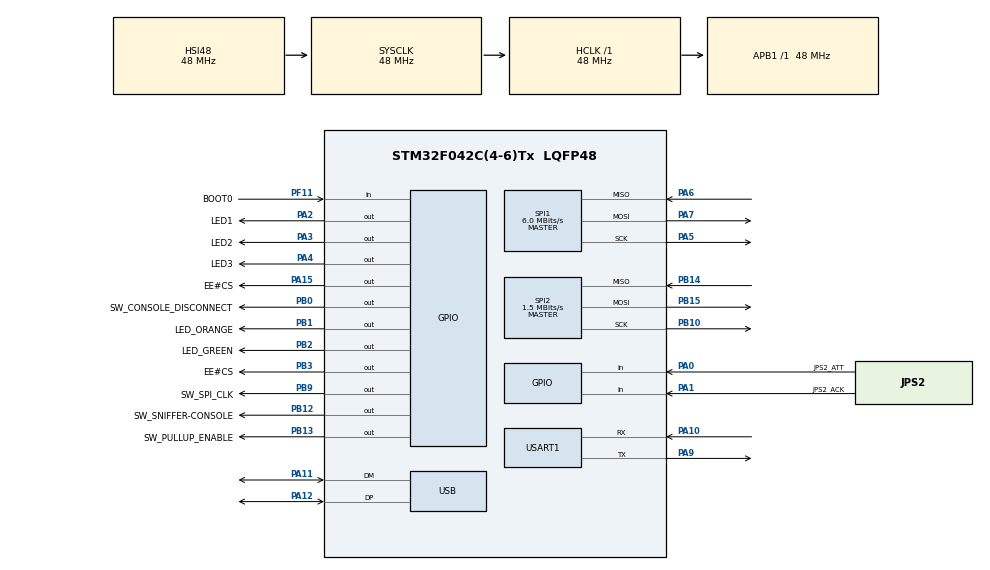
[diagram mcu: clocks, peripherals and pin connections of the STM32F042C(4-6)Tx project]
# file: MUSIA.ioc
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IWDG.Prescaler=IWDG_PRESCALER_32
Mcu.Family=STM32F0
Mcu.Name=STM32F042C(4-6)Tx
Mcu.Package=LQFP48
NVIC.USB_IRQn=true\:0\:0\:false\:false\:true\:false
PA0.GPIO_Label=JPS2_ATT
PA0.Signal=GPIO_Input
PA1.GPIO_Label=JPS2_ACK
PA1.Signal=GPIO_Input
PA10.Mode=Asynchronous
PA10.Signal=USART1_RX
PA11.Mode=Device
PA11.Signal=USB_DM
PA12.Mode=Device
PA12.Signal=USB_DP
PA13.Mode=Serial_Wire
PA13.Signal=SYS_SWDIO
PA14.Mode=Serial_Wire
PA14.Signal=SYS_SWCLK
PA15.GPIO_Label=EE\#CS
PA15.Signal=GPIO_Output
PA2.GPIO_Label=LED1
PA2.Signal=GPIO_Output
PA3.GPIO_Label=LED2
PA3.Signal=GPIO_Output
PA4.GPIO_Label=LED3
PA4.Signal=GPIO_Output
PA5.Mode=Full_Duplex_Master
PA5.Signal=SPI1_SCK
PA6.Mode=Full_Duplex_Master
PA6.Signal=SPI1_MISO
PA7.Mode=Full_Duplex_Master
PA7.Signal=SPI1_MOSI
PA9.Mode=Asynchronous
PA9.Signal=USART1_TX
PB0.GPIO_Label=SW_CONSOLE_DISCONNECT
PB0.Signal=GPIO_Output
PB1.GPIO_Label=LED_ORANGE
PB1.Signal=GPIO_Output
PB10.Mode=Full_Duplex_Master
PB10.Signal=SPI2_SCK
PB12.GPIO_Label=SW_SNIFFER-CONSOLE
PB12.Signal=GPIO_Output
PB13.GPIO_Label=SW_PULLUP_ENABLE
PB13.Signal=GPIO_Output
PB14.Mode=Full_Duplex_Master
PB14.Signal=SPI2_MISO
PB15.Mode=Full_Duplex_Master
PB15.Signal=SPI2_MOSI
PB2.GPIO_Label=LED_GREEN
PB2.Signal=GPIO_Output
PB3.GPIO_Label=EE\#CS
PB3.Signal=GPIO_Output
PB9.GPIO_Label=SW_SPI_CLK
PB9.Signal=GPIO_Output
PC14OSC32_IN.GPIO_Label=USB_VIBR_EN
PC14OSC32_IN.Signal=GPIO_Output
PC15OSC32_OUT.GPIO_Label=PS2_VIBR_EN
PC15OSC32_OUT.Signal=GPIO_Output
PF11.GPIO_Label=BOOT0
PF11.Signal=GPIO_Input
ProjectManager.HeapSize=0x200
ProjectManager.StackSize=0x400
ProjectManager.TargetToolchain=Other Toolchains (GPDSC)
RCC.AHBFreq_Value=48000000
RCC.APB1Freq_Value=48000000
RCC.APB1TimFreq_Value=48000000
RCC.HCLKFreq_Value=48000000
RCC.SYSCLKFreq_VALUE=48000000
RCC.SYSCLKSource=RCC_SYSCLKSOURCE_HSI48
SPI1.BaudRatePrescaler=SPI_BAUDRATEPRESCALER_8
SPI1.CalculateBaudRate=6.0 MBits/s
SPI1.Direction=SPI_DIRECTION_2LINES
SPI1.Mode=SPI_MODE_MASTER
SPI1.VirtualType=VM_MASTER
SPI2.BaudRatePrescaler=SPI_BAUDRATEPRESCALER_32
SPI2.CalculateBaudRate=1.5 MBits/s
SPI2.Direction=SPI_DIRECTION_2LINES
SPI2.Mode=SPI_MODE_MASTER
SPI2.VirtualType=VM_MASTER
USART1.VirtualMode-Asynchronous=VM_ASYNC
USB_DEVICE.CLASS_NAME_FS=HID
USB_DEVICE.VirtualMode=Hid
USB_DEVICE.VirtualModeFS=Hid_FS
VP_IWDG_VS_IWDG.Mode=IWDG_Activate
VP_USB_DEVICE_VS_USB_DEVICE_HID_FS.Mode=HID_FS
board=custom

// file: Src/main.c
/**
  ******************************************************************************
  * @file           : main.c
  * @brief          : Main program body
  ******************************************************************************
  * This notice applies to any and all portions of this file
  * that are not between comment pairs USER CODE BEGIN and
  * USER CODE END. Other portions of this file, whether
  * inserted by the user or by software development tools
  * are owned by their respective copyright owners.
  *
  * Copyright (c) 2018 STMicroelectronics International N.V.
  * All rights reserved.
  *
  * Redistribution and use in source and binary forms, with or without
  * modification, are permitted, provided that the following conditions are met:
  *
  * 1. Redistribution of source code must retain the above copyright notice,
  *    this list of conditions and the following disclaimer.
  * 2. Redistributions in binary form must reproduce the above copyright notice,
  *    this list of conditions and the following disclaimer in the documentation
  *    and/or other materials provided with the distribution.
  * 3. Neither the name of STMicroelectronics nor the names of other
  *    contributors to this software may be used to endorse or promote products
  *    derived from this software without specific written permission.
  * 4. This software, including modifications and/or derivative works of this
  *    software, must execute solely and exclusively on microcontroller or
  *    microprocessor devices manufactured by or for STMicroelectronics.
  * 5. Redistribution and use of this software other than as permitted under
  *    this license is void and will automatically terminate your rights under
  *    this license.
  *
  * THIS SOFTWARE IS PROVIDED BY STMICROELECTRONICS AND CONTRIBUTORS "AS IS"
  * AND ANY EXPRESS, IMPLIED OR STATUTORY WARRANTIES, INCLUDING, BUT NOT
  * LIMITED TO, THE IMPLIED WARRANTIES OF MERCHANTABILITY, FITNESS FOR A
  * PARTICULAR PURPOSE AND NON-INFRINGEMENT OF THIRD PARTY INTELLECTUAL PROPERTY
  * RIGHTS ARE DISCLAIMED TO THE FULLEST EXTENT PERMITTED BY LAW. IN NO EVENT
  * SHALL STMICROELECTRONICS OR CONTRIBUTORS BE LIABLE FOR ANY DIRECT, INDIRECT,
  * INCIDENTAL, SPECIAL, EXEMPLARY, OR CONSEQUENTIAL DAMAGES (INCLUDING, BUT NOT
  * LIMITED TO, PROCUREMENT OF SUBSTITUTE GOODS OR SERVICES; LOSS OF USE, DATA,
  * OR PROFITS; OR BUSINESS INTERRUPTION) HOWEVER CAUSED AND ON ANY THEORY OF
  * LIABILITY, WHETHER IN CONTRACT, STRICT LIABILITY, OR TORT (INCLUDING
  * NEGLIGENCE OR OTHERWISE) ARISING IN ANY WAY OUT OF THE USE OF THIS SOFTWARE,
  * EVEN IF ADVISED OF THE POSSIBILITY OF SUCH DAMAGE.
  *
  ******************************************************************************
  */
#include "main.h"
#include "stm32f0xx_hal.h"
#include "iwdg.h"
#include "spi.h"
#include "usart.h"
#include "usb_device.h"
#include "gpio.h"

/* USER CODE BEGIN Includes */
extern int musia_main();
/* USER CODE END Includes */

/* USER CODE BEGIN PV */
/* Private variables ---------------------------------------------------------*/

/* USER CODE END PV */

void SystemClock_Config(void);

/* USER CODE BEGIN PFP */
/* Private function prototypes -----------------------------------------------*/

/* USER CODE END PFP */

int main(void)
{

  /* MCU Configuration----------------------------------------------------------*/

  /* Reset of all peripherals, Initializes the Flash interface and the Systick. */
  HAL_Init();

  /* Configure the system clock */
  SystemClock_Config();

  /* Initialize all configured peripherals */
  MX_GPIO_Init();
  MX_IWDG_Init();
  MX_SPI1_Init();
  MX_SPI2_Init();
  MX_USART1_UART_Init();
  MX_USB_DEVICE_Init();

  /* Infinite loop */
  while (1)
  {

  }

}

void SystemClock_Config(void)
{

  RCC_OscInitTypeDef RCC_OscInitStruct;
  RCC_ClkInitTypeDef RCC_ClkInitStruct;
  RCC_PeriphCLKInitTypeDef PeriphClkInit;

    /**Initializes the CPU, AHB and APB busses clocks
    */
  RCC_OscInitStruct.OscillatorType = RCC_OSCILLATORTYPE_HSI48|RCC_OSCILLATORTYPE_LSI;
  RCC_OscInitStruct.HSI48State = RCC_HSI48_ON;
  RCC_OscInitStruct.LSIState = RCC_LSI_ON;
  RCC_OscInitStruct.PLL.PLLState = RCC_PLL_NONE;
  if (HAL_RCC_OscConfig(&RCC_OscInitStruct) != HAL_OK)
  {
    _Error_Handler(__FILE__, __LINE__);
  }

    /**Initializes the CPU, AHB and APB busses clocks
    */
  RCC_ClkInitStruct.ClockType = RCC_CLOCKTYPE_HCLK|RCC_CLOCKTYPE_SYSCLK
                              |RCC_CLOCKTYPE_PCLK1;
  RCC_ClkInitStruct.SYSCLKSource = RCC_SYSCLKSOURCE_HSI48;
  RCC_ClkInitStruct.AHBCLKDivider = RCC_SYSCLK_DIV1;
  RCC_ClkInitStruct.APB1CLKDivider = RCC_HCLK_DIV1;

  if (HAL_RCC_ClockConfig(&RCC_ClkInitStruct, FLASH_LATENCY_1) != HAL_OK)
  {
    _Error_Handler(__FILE__, __LINE__);
  }

  PeriphClkInit.PeriphClockSelection = RCC_PERIPHCLK_USB|RCC_PERIPHCLK_USART1;
  PeriphClkInit.Usart1ClockSelection = RCC_USART1CLKSOURCE_PCLK1;
  PeriphClkInit.UsbClockSelection = RCC_USBCLKSOURCE_HSI48;

  if (HAL_RCCEx_PeriphCLKConfig(&PeriphClkInit) != HAL_OK)
  {
    _Error_Handler(__FILE__, __LINE__);
  }

    /**Configure the Systick interrupt time
    */
  HAL_SYSTICK_Config(HAL_RCC_GetHCLKFreq()/1000);

    /**Configure the Systick
    */
  HAL_SYSTICK_CLKSourceConfig(SYSTICK_CLKSOURCE_HCLK);

  /* SysTick_IRQn interrupt configuration */
  HAL_NVIC_SetPriority(SysTick_IRQn, 0, 0);
}

void _Error_Handler(char *file, int line)
{
  while(1)
  {
  }
}

/************************ (C) COPYRIGHT STMicroelectronics *****END OF FILE****/
